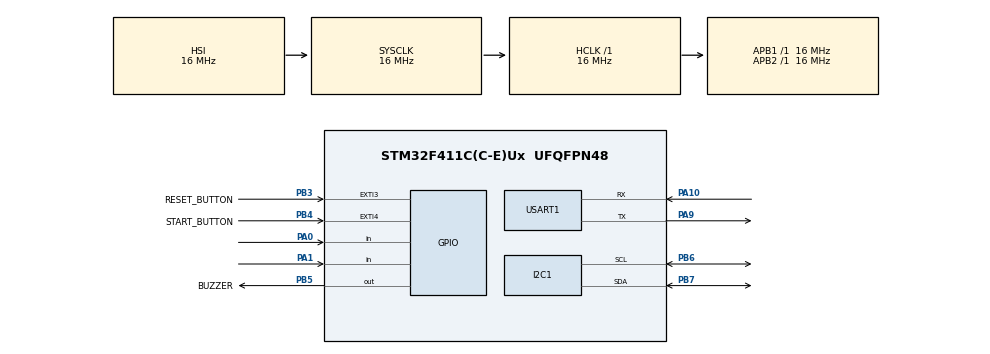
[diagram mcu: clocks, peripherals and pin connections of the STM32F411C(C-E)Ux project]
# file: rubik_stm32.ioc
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I2C1.DutyCycle=I2C_DUTYCYCLE_2
I2C1.I2C_Mode=I2C_Fast
Mcu.Family=STM32F4
Mcu.Name=STM32F411C(C-E)Ux
Mcu.Package=UFQFPN48
NVIC.EXTI3_IRQn=true\:0\:0\:false\:false\:true\:true\:true\:true
NVIC.EXTI4_IRQn=true\:0\:0\:false\:false\:true\:true\:true\:true
NVIC.I2C1_ER_IRQn=true\:0\:0\:false\:false\:true\:true\:true\:true
NVIC.I2C1_EV_IRQn=true\:0\:0\:false\:false\:true\:true\:true\:true
NVIC.PriorityGroup=NVIC_PRIORITYGROUP_4
NVIC.USART1_IRQn=true\:0\:0\:false\:false\:true\:true\:true\:true
PA0-WKUP.Signal=GPIO_Input
PA1.Signal=GPIO_Input
PA10.Mode=Asynchronous
PA10.Signal=USART1_RX
PA13.Mode=Serial_Wire
PA13.Signal=SYS_JTMS-SWDIO
PA14.Mode=Serial_Wire
PA14.Signal=SYS_JTCK-SWCLK
PA9.Mode=Asynchronous
PA9.Signal=USART1_TX
PB3.GPIO_Label=RESET_BUTTON
PB3.GPIO_ModeDefaultEXTI=GPIO_MODE_IT_FALLING
PB3.GPIO_PuPd=GPIO_PULLUP
PB3.Signal=GPXTI3
PB4.GPIO_Label=START_BUTTON
PB4.GPIO_ModeDefaultEXTI=GPIO_MODE_IT_FALLING
PB4.GPIO_PuPd=GPIO_PULLUP
PB4.Signal=GPXTI4
PB5.GPIO_Label=BUZZER
PB5.Signal=GPIO_Output
PB6.GPIO_Pu=GPIO_NOPULL
PB6.Mode=I2C
PB6.Signal=I2C1_SCL
PB7.GPIO_Pu=GPIO_NOPULL
PB7.GPIO_Speed=GPIO_SPEED_FREQ_VERY_HIGH
PB7.Mode=I2C
PB7.Signal=I2C1_SDA
ProjectManager.HeapSize=0x200
ProjectManager.StackSize=0x400
ProjectManager.TargetToolchain=STM32CubeIDE
RCC.AHBFreq_Value=16000000
RCC.APB1Freq_Value=16000000
RCC.APB2Freq_Value=16000000
RCC.CortexFreq_Value=16000000
RCC.HSE_VALUE=25000000
RCC.HSI_VALUE=16000000
RCC.LSE_VALUE=32768
RCC.SYSCLKFreq_VALUE=16000000
RCC.VCOOutputFreq_Value=192000000
USART1.VirtualMode=VM_ASYNC
board=custom

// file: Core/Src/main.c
/* USER CODE BEGIN Header */
/**
  ******************************************************************************
  * @file           : main.c
  * @brief          : Main program body
  ******************************************************************************
  * @attention
  *
  * Copyright (c) 2026 STMicroelectronics.
  * All rights reserved.
  *
  * This software is licensed under terms that can be found in the LICENSE file
  * in the root directory of this software component.
  * If no LICENSE file comes with this software, it is provided AS-IS.
  *
  ******************************************************************************
  */
/* USER CODE END Header */
#include "main.h"

/* USER CODE BEGIN Includes */
#include "../../Hardware/PCA9685/PCA9685.h"
#include "../../Hardware/UART_Handle/UART_Handle.h"
#include "../../Hardware/Servo_Control/Servo_Control.h"
#include "../../Hardware/Rubik_Control/Rubik_Control.h"
/* USER CODE END Includes */

I2C_HandleTypeDef hi2c1;

UART_HandleTypeDef huart1;

void SystemClock_Config(void);
static void MX_GPIO_Init(void);
static void MX_I2C1_Init(void);
static void MX_USART1_UART_Init(void);

int main(void)
{

  /* MCU Configuration--------------------------------------------------------*/

  /* Reset of all peripherals, Initializes the Flash interface and the Systick. */
  HAL_Init();

  /* Configure the system clock */
  SystemClock_Config();

  /* Initialize all configured peripherals */
  MX_GPIO_Init();
  MX_I2C1_Init();
  MX_USART1_UART_Init();
  /* USER CODE BEGIN 2 */
  UART_Command_Init(&huart1);
  static const uint8_t uart_alive[] = "Hello from alive STM32 USART1\r\n";
  HAL_UART_Transmit(&huart1, uart_alive, sizeof(uart_alive) - 1U, 20U);
  PCA9685_Init(50); // 50Hz for servo
  Servo_Init();
  Servo_Start_Position();
  Rubik_Hold_Start_Position();
  // UART_Command_Init(&huart1);
  /* USER CODE END 2 */

  /* Infinite loop */
  while (1)
  {

    /* USER CODE BEGIN 3 */
    //UART_Handle_Process();
	  //Rubik_Left();
	  //HAL_Delay(3000);
	 UART_Command_Process();
     //UART_Accept(1);
     //UART_Done(1);
     //UART_Error(1, "Test error");
     //HAL_Delay(1000);

  }
  /* USER CODE END 3 */
}

void SystemClock_Config(void)
{
  RCC_OscInitTypeDef RCC_OscInitStruct = {0};
  RCC_ClkInitTypeDef RCC_ClkInitStruct = {0};

  /** Configure the main internal regulator output voltage
  */
  __HAL_RCC_PWR_CLK_ENABLE();
  __HAL_PWR_VOLTAGESCALING_CONFIG(PWR_REGULATOR_VOLTAGE_SCALE1);

  /** Initializes the RCC Oscillators according to the specified parameters
  * in the RCC_OscInitTypeDef structure.
  */
  RCC_OscInitStruct.OscillatorType = RCC_OSCILLATORTYPE_HSI;
  RCC_OscInitStruct.HSIState = RCC_HSI_ON;
  RCC_OscInitStruct.HSICalibrationValue = RCC_HSICALIBRATION_DEFAULT;
  RCC_OscInitStruct.PLL.PLLState = RCC_PLL_NONE;
  if (HAL_RCC_OscConfig(&RCC_OscInitStruct) != HAL_OK)
  {
    Error_Handler();
  }

  /** Initializes the CPU, AHB and APB buses clocks
  */
  RCC_ClkInitStruct.ClockType = RCC_CLOCKTYPE_HCLK|RCC_CLOCKTYPE_SYSCLK
                              |RCC_CLOCKTYPE_PCLK1|RCC_CLOCKTYPE_PCLK2;
  RCC_ClkInitStruct.SYSCLKSource = RCC_SYSCLKSOURCE_HSI;
  RCC_ClkInitStruct.AHBCLKDivider = RCC_SYSCLK_DIV1;
  RCC_ClkInitStruct.APB1CLKDivider = RCC_HCLK_DIV1;
  RCC_ClkInitStruct.APB2CLKDivider = RCC_HCLK_DIV1;

  if (HAL_RCC_ClockConfig(&RCC_ClkInitStruct, FLASH_LATENCY_0) != HAL_OK)
  {
    Error_Handler();
  }
}

static void MX_I2C1_Init(void)
{

  hi2c1.Instance = I2C1;
  hi2c1.Init.ClockSpeed = 400000;
  hi2c1.Init.DutyCycle = I2C_DUTYCYCLE_2;
  hi2c1.Init.OwnAddress1 = 0;
  hi2c1.Init.AddressingMode = I2C_ADDRESSINGMODE_7BIT;
  hi2c1.Init.DualAddressMode = I2C_DUALADDRESS_DISABLE;
  hi2c1.Init.OwnAddress2 = 0;
  hi2c1.Init.GeneralCallMode = I2C_GENERALCALL_DISABLE;
  hi2c1.Init.NoStretchMode = I2C_NOSTRETCH_DISABLE;
  if (HAL_I2C_Init(&hi2c1) != HAL_OK)
  {
    Error_Handler();
  }

}

static void MX_USART1_UART_Init(void)
{

  huart1.Instance = USART1;
  huart1.Init.BaudRate = 115200;
  huart1.Init.WordLength = UART_WORDLENGTH_8B;
  huart1.Init.StopBits = UART_STOPBITS_1;
  huart1.Init.Parity = UART_PARITY_NONE;
  huart1.Init.Mode = UART_MODE_TX_RX;
  huart1.Init.HwFlowCtl = UART_HWCONTROL_NONE;
  huart1.Init.OverSampling = UART_OVERSAMPLING_16;
  if (HAL_UART_Init(&huart1) != HAL_OK)
  {
    Error_Handler();
  }

}

static void MX_GPIO_Init(void)
{
  GPIO_InitTypeDef GPIO_InitStruct = {0};

  /* GPIO Ports Clock Enable */
  __HAL_RCC_GPIOA_CLK_ENABLE();
  __HAL_RCC_GPIOB_CLK_ENABLE();

  /*Configure GPIO pin Output Level */
  HAL_GPIO_WritePin(BUZZER_GPIO_Port, BUZZER_Pin, GPIO_PIN_RESET);

  /*Configure GPIO pins : PA0 PA1 */
  GPIO_InitStruct.Pin = GPIO_PIN_0|GPIO_PIN_1;
  GPIO_InitStruct.Mode = GPIO_MODE_INPUT;
  GPIO_InitStruct.Pull = GPIO_NOPULL;
  HAL_GPIO_Init(GPIOA, &GPIO_InitStruct);

  /*Configure GPIO pins : RESET_BUTTON_Pin START_BUTTON_Pin */
  GPIO_InitStruct.Pin = RESET_BUTTON_Pin|START_BUTTON_Pin;
  GPIO_InitStruct.Mode = GPIO_MODE_IT_FALLING;
  GPIO_InitStruct.Pull = GPIO_PULLUP;
  HAL_GPIO_Init(GPIOB, &GPIO_InitStruct);

  /*Configure GPIO pin : BUZZER_Pin */
  GPIO_InitStruct.Pin = BUZZER_Pin;
  GPIO_InitStruct.Mode = GPIO_MODE_OUTPUT_PP;
  GPIO_InitStruct.Pull = GPIO_NOPULL;
  GPIO_InitStruct.Speed = GPIO_SPEED_FREQ_LOW;
  HAL_GPIO_Init(BUZZER_GPIO_Port, &GPIO_InitStruct);

  /* EXTI interrupt init*/
  HAL_NVIC_SetPriority(EXTI3_IRQn, 0, 0);
  HAL_NVIC_EnableIRQ(EXTI3_IRQn);

  HAL_NVIC_SetPriority(EXTI4_IRQn, 0, 0);
  HAL_NVIC_EnableIRQ(EXTI4_IRQn);

}

/* USER CODE BEGIN 4 */
void HAL_UART_RxCpltCallback(UART_HandleTypeDef *huart)
{
    UART_Command_RxCallback(huart);
}

/* USER CODE END 4 */

void Error_Handler(void)
{
  __disable_irq();
  while (1)
  {
  }
}
